# GD32E511_512 register map
File version: 1.0
CPU: CM33 r0p4, little endian, MPU, FPU, 4 interrupt priority bits
Registers are 32-bit, read-write, reset 0x0 unless marked. A register's access mark holds for its fields unless they carry their own. Offsets are from the block's base; [hi:lo] are bit positions; 'fields as' and 'values as' point back to an identical list.

## FMC
Base 0x40022000
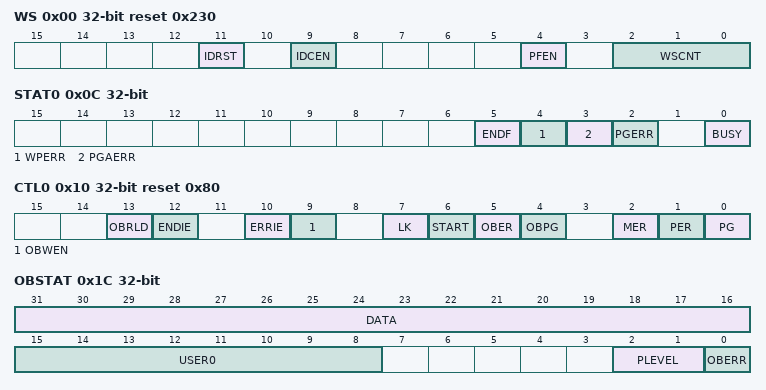
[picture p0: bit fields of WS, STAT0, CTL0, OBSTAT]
0x00 WS reset 0x230 — Wait state register
  [11] IDRST — Cache reset
  [9] IDCEN — Cache enable
  [4] PFEN — Pre-fetch enable
  [2:0] WSCNT — Wait state counter register
0x04 KEY0 wo — Unlock key register0
  [31:0] KEY — FMC_CTL0 unlock registers
0x08 OBKEY wo — Option byte unlock key register
  [31:0] OBKEY — FMC_CTL0 option byte operation unlock registers
0x0C STAT0 access per field — Status register0
  [5] ENDF rw — End of operation flag bit
  [4] WPERR rw — Erase/Program protection error flag bit
  [3] PGAERR rw — Program alignment error flag bit
  [2] PGERR rw — Program error flag bit
  [0] BUSY ro — The flash busy bit
0x10 CTL0 reset 0x80 — Control register0
  [13] OBRLD — Option byte reload bit
  [12] ENDIE — End of operation interrupt enable bit
  [10] ERRIE — Error interrupt enable bit
  [9] OBWEN — Option byte erase/program enable bit
  [7] LK — FMC_CTL0 lock bit
  [6] START — Send erase command to FMC bit
  [5] OBER — Option byte erase command bit
  [4] OBPG — Option byte program command bit
  [2] MER — Main flash mass erase command bit
  [1] PER — Main flash page erase command bit
  [0] PG — Main flash page program command bit
0x14 ADDR0 wo — Address register0
  [31:0] ADDR — Flash command address bits
0x1C OBSTAT ro — Option byte status register
  [31:16] DATA — Store OB_DATA[15:0] of option byte block after system reset
  [15:8] USER0 — Store OB_USER0 byte of option byte block after system reset
  [2:1] PLEVEL — Security Protection level
  [0] OBERR — Option byte read error bit.
0x20 WP ro — Write protection register
  [31:0] WP — Store OB_WP[31:0] of option byte block after system reset
0x44 KEY1 wo — Unlock key register1
  [31:0] KEY — FMC_CTL1 unlock registers
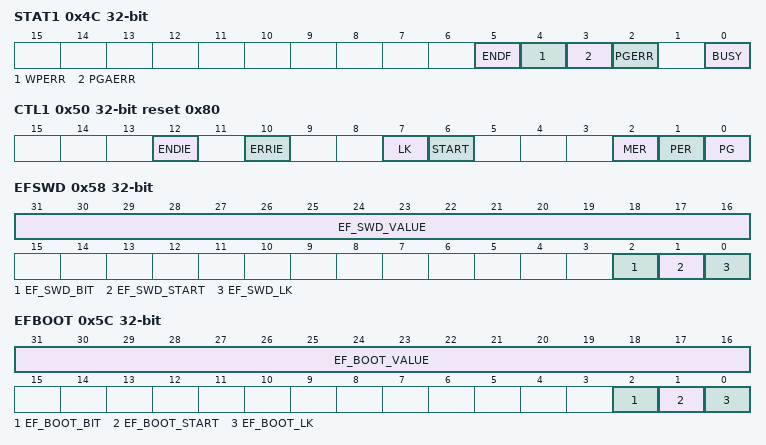
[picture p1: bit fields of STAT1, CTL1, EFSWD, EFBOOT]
0x4C STAT1 access per field — Status register1
  fields as STAT0
0x50 CTL1 reset 0x80 — Control register1
  [12] ENDIE — End of operation interrupt enable bit
  [10] ERRIE — Error interrupt enable bit
  [7] LK — FMC_CTL1 lock bit
  [6] START — Send erase command to FMC bit
  [2] MER — Main flash mass erase command bit
  [1] PER — Main flash page erase command bit
  [0] PG — Main flash page program command bit
0x54 ADDR1 wo — Address register1
  [31:0] ADDR — Flash command address bits
0x58 EFSWD access per field — Efuse SWD protection register
  [31:16] EF_SWD_VALUE rw — This field load EF_SWD_VALUE from e-flash when system reset. This field can be written by software.
  [2] EF_SWD_BIT ro — Read only, when EF_SWD_VALUE is 0x33CC, set 1. Otherwise set 0
  [1] EF_SWD_START rw — This bit triggers an operation after writing EF_SWD_VALUE to e-flash. It is set only by software and cleared when the BUSY bit is cleared
  [0] EF_SWD_LK ro — Read only'when EF_SWD_VALUE if not 0xFFFF, set EF_SWD_LK 1. When EF_SWD_LK is 1, this register can`t be configured anymore.
0x5C EFBOOT access per field — Efuse BOOT protection register
  [31:16] EF_BOOT_VALUE rw — This field load EF_BOOT_VALUE from e-flash when system reset. This field can be written by software.
  [2] EF_BOOT_BIT ro — Read only, when EF_BOOT_VALUE is 0x33CC, set 1. Otherwise set 0
  [1] EF_BOOT_START rw — This bit triggers an operation after writing EF_BOOT_VALUE to e-flash. It is set only by software and cleared when the BUSY bit is cleared
  [0] EF_BOOT_LK ro — Read only'when EF_BOOT_VALUE if not 0xFFFF, set EF_BOOT_LK 1. When EF_BOOT_LK is 1, this register can`t be configured anymore.
0x100 PID ro — Product ID register
  [31:0] PID — Product reserved ID code register
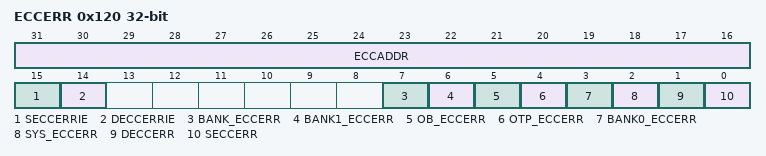
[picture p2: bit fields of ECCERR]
0x120 ECCERR access per field — ECC error register
  [31:16] ECCADDR ro — The offset address of four word where an ECC error is detected.
  [15] SECCERRIE rw — Single bit error correct interrupt enable.
  [14] DECCERRIE rw — Double bit errors detect interrupt enable.
  [7] BANK_ECCERR ro — This bit is used to indicate which bank of the flash has generated an ECC error.
  [6] BANK1_ECCERR rw — If an ECC bit error is detected in Bank1 flash, this bit will be set. And the ECCADDR records the offset address of main Flash. DECCERR bit and SECCERR bit indicate there is a single bit error or a double bit error. This bit is cleared by writing 1.
  [5] OB_ECCERR rw — If an ECC bit error is detected in reading option bytes, this bit will be set. And the ECCADDR records the offset address of option bytes. DECCERR bit and SECCERR bit indicate there is a single bit error or a double bit error. This bit is cleared by writing 1.
  [4] OTP_ECCERR rw — If an ECC bit error is detected in OTP, this bit will be set. And the ECCADDR records the offset address of OTP. DECCERR bit and SECCERR bit indicate there is a single bit error or a double bit error. This bit is cleared by writing 1.
  [3] BANK0_ECCERR rw — If an ECC bit error is detected in Bank0 Flash, this bit will be set. And the ECCADDR records the offset address of main Flash. SECCERR bit and DECCERR bit indicate there is a single bit error or a double bit error. This bit is cleared by writing 1.
  [2] SYS_ECCERR rw — If an ECC bit error is detected in system memory, this bit will be set. And the ECCADDR records the offset address of system memory. SECCERR bit and DECCERR bit indicate there is a single bit error or a double bit error. This bit is cleared by writing 1.
  [1] DECCERR rw — Double bit errors detect flag. This bit set when two bit errors is detected.
  [0] SECCERR rw — Single bit error detected and correct flag.
